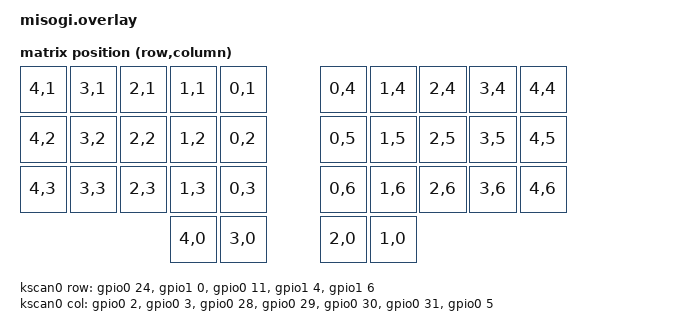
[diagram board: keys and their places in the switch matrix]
// This file was generated from a template. Edit it to match your keyboard.
// See https://zmk.dev/docs/development/hardware-integration/new-shield for more
// instructions.

#include <dt-bindings/zmk/matrix_transform.h>
#include <dt-bindings/led/led.h>

/ {
    chosen {
        zmk,kscan = &kscan0;
        zmk,matrix_transform = &default_transform;
        zmk,underglow = &led_strip;
    };

    default_transform: key_transform {
        compatible = "zmk,matrix-transform";
        columns = <7>;
        rows = <5>;
        map = <
            RC(4,1) RC(3,1) RC(2,1) RC(1,1) RC(0,1)    RC(0,4) RC(1,4) RC(2,4) RC(3,4) RC(4,4)
            RC(4,2) RC(3,2) RC(2,2) RC(1,2) RC(0,2)    RC(0,5) RC(1,5) RC(2,5) RC(3,5) RC(4,5)
            RC(4,3) RC(3,3) RC(2,3) RC(1,3) RC(0,3)    RC(0,6) RC(1,6) RC(2,6) RC(3,6) RC(4,6)
                            RC(4,0) RC(3,0)            RC(2,0) RC(1,0)
        >;
    };

    kscan0: kscan {
        compatible = "zmk,kscan-gpio-matrix";
        diode-direction = "col2row";

        row-gpios
            = <&gpio0 24 (GPIO_ACTIVE_HIGH | GPIO_PULL_DOWN)> // Pro Micro 5
            , <&gpio1 0  (GPIO_ACTIVE_HIGH | GPIO_PULL_DOWN)> // Pro Micro 6
            , <&gpio0 11 (GPIO_ACTIVE_HIGH | GPIO_PULL_DOWN)> // Pro Micro 7
            , <&gpio1 4  (GPIO_ACTIVE_HIGH | GPIO_PULL_DOWN)> // Pro Micro 8
            , <&gpio1 6  (GPIO_ACTIVE_HIGH | GPIO_PULL_DOWN)> // Pro Micro 9
            ;

        col-gpios
            = <&gpio0 2  GPIO_ACTIVE_HIGH> // Pro Micro 20
            , <&gpio0 3  GPIO_ACTIVE_HIGH> // Pro Micro 19
            , <&gpio0 28 GPIO_ACTIVE_HIGH> // Pro Micro 18
            , <&gpio0 29 GPIO_ACTIVE_HIGH> // Pro Micro 17
            , <&gpio0 30 GPIO_ACTIVE_HIGH> // Pro Micro 16
            , <&gpio0 31 GPIO_ACTIVE_HIGH> // Pro Micro 15
            , <&gpio0 5  GPIO_ACTIVE_HIGH> // Pro Micro 14
            ;
    };
};

/* SPI config for LED */
&pinctrl {
    spi0_default: spi0_default {
        group1 {
            psels = <NRF_PSEL(SPIM_MOSI, 0, 6)>; // Pin 6 for LED
        };
    };

    spi0_sleep: spi0_sleep {
        group1 {
            psels = <NRF_PSEL(SPIM_MOSI, 0, 6)>;
            low-power-enable;
        };
    };
};

&spi0 {
    compatible = "nordic,nrf-spim";
    status = "okay";
    pinctrl-0 = <&spi0_default>;
    pinctrl-1 = <&spi0_sleep>;
    pinctrl-names = "default", "sleep";

    led_strip: ws2812@0 {
        compatible = "worldsemi,ws2812-spi";
        label = "WS2812";

        /* SPI */
        reg = <0>;
        spi-max-frequency = <4000000>;

        /* WS2812 */
        chain-length = <34>;
        spi-one-frame = <0x70>;
        spi-zero-frame = <0x40>;
        color-mapping = <LED_COLOR_ID_GREEN LED_COLOR_ID_RED LED_COLOR_ID_BLUE>;
    };
};
